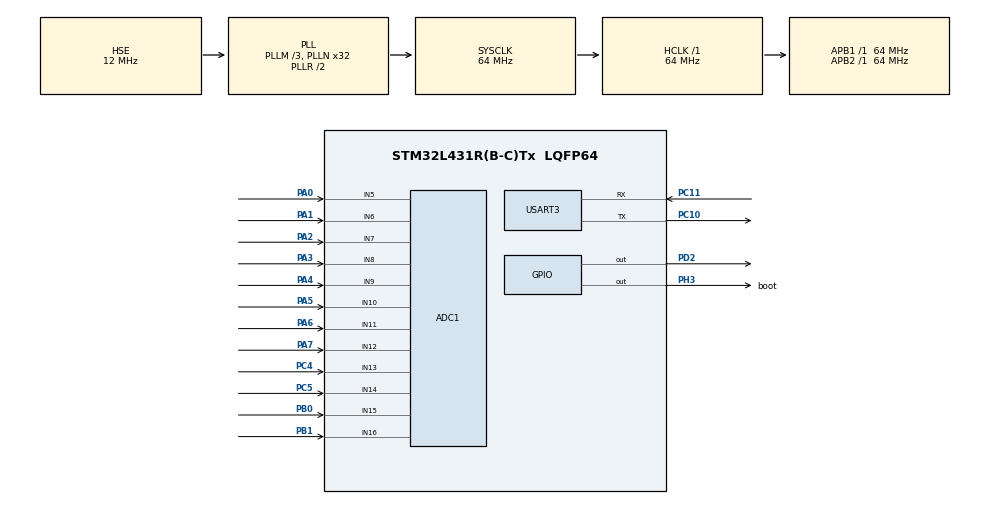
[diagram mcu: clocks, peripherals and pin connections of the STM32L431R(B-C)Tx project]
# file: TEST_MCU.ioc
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ADC1.Channel-0\#ChannelRegularConversion=ADC_CHANNEL_5
ADC1.Channel-1\#ChannelRegularConversion=ADC_CHANNEL_6
ADC1.Channel-10\#ChannelRegularConversion=ADC_CHANNEL_15
ADC1.Channel-11\#ChannelRegularConversion=ADC_CHANNEL_16
ADC1.Channel-2\#ChannelRegularConversion=ADC_CHANNEL_7
ADC1.Channel-3\#ChannelRegularConversion=ADC_CHANNEL_8
ADC1.Channel-4\#ChannelRegularConversion=ADC_CHANNEL_9
ADC1.Channel-5\#ChannelRegularConversion=ADC_CHANNEL_10
ADC1.Channel-6\#ChannelRegularConversion=ADC_CHANNEL_11
ADC1.Channel-7\#ChannelRegularConversion=ADC_CHANNEL_12
ADC1.Channel-8\#ChannelRegularConversion=ADC_CHANNEL_13
ADC1.Channel-9\#ChannelRegularConversion=ADC_CHANNEL_14
ADC1.ContinuousConvMode=ENABLE
ADC1.DMAContinuousRequests=ENABLE
ADC1.EOCSelection=ADC_EOC_SEQ_CONV
ADC1.NbrOfConversion=12
ADC1.NbrOfConversionFlag=1
ADC1.OffsetNumber-0\#ChannelRegularConversion=ADC_OFFSET_NONE
ADC1.OffsetNumber-1\#ChannelRegularConversion=ADC_OFFSET_NONE
ADC1.OffsetNumber-10\#ChannelRegularConversion=ADC_OFFSET_NONE
ADC1.OffsetNumber-11\#ChannelRegularConversion=ADC_OFFSET_NONE
ADC1.OffsetNumber-2\#ChannelRegularConversion=ADC_OFFSET_NONE
ADC1.OffsetNumber-3\#ChannelRegularConversion=ADC_OFFSET_NONE
ADC1.OffsetNumber-4\#ChannelRegularConversion=ADC_OFFSET_NONE
ADC1.OffsetNumber-5\#ChannelRegularConversion=ADC_OFFSET_NONE
ADC1.OffsetNumber-6\#ChannelRegularConversion=ADC_OFFSET_NONE
ADC1.OffsetNumber-7\#ChannelRegularConversion=ADC_OFFSET_NONE
ADC1.OffsetNumber-8\#ChannelRegularConversion=ADC_OFFSET_NONE
ADC1.OffsetNumber-9\#ChannelRegularConversion=ADC_OFFSET_NONE
ADC1.Overrun=ADC_OVR_DATA_OVERWRITTEN
ADC1.Rank-0\#ChannelRegularConversion=1
ADC1.Rank-1\#ChannelRegularConversion=2
ADC1.Rank-10\#ChannelRegularConversion=11
ADC1.Rank-11\#ChannelRegularConversion=12
ADC1.Rank-2\#ChannelRegularConversion=3
ADC1.Rank-3\#ChannelRegularConversion=4
ADC1.Rank-4\#ChannelRegularConversion=5
ADC1.Rank-5\#ChannelRegularConversion=6
ADC1.Rank-6\#ChannelRegularConversion=7
ADC1.Rank-7\#ChannelRegularConversion=8
ADC1.Rank-8\#ChannelRegularConversion=9
ADC1.Rank-9\#ChannelRegularConversion=10
ADC1.SamplingTime-0\#ChannelRegularConversion=ADC_SAMPLETIME_640CYCLES_5
ADC1.SamplingTime-1\#ChannelRegularConversion=ADC_SAMPLETIME_640CYCLES_5
ADC1.SamplingTime-10\#ChannelRegularConversion=ADC_SAMPLETIME_640CYCLES_5
ADC1.SamplingTime-11\#ChannelRegularConversion=ADC_SAMPLETIME_640CYCLES_5
ADC1.SamplingTime-2\#ChannelRegularConversion=ADC_SAMPLETIME_640CYCLES_5
ADC1.SamplingTime-3\#ChannelRegularConversion=ADC_SAMPLETIME_640CYCLES_5
ADC1.SamplingTime-4\#ChannelRegularConversion=ADC_SAMPLETIME_640CYCLES_5
ADC1.SamplingTime-5\#ChannelRegularConversion=ADC_SAMPLETIME_640CYCLES_5
ADC1.SamplingTime-6\#ChannelRegularConversion=ADC_SAMPLETIME_640CYCLES_5
ADC1.SamplingTime-7\#ChannelRegularConversion=ADC_SAMPLETIME_640CYCLES_5
ADC1.SamplingTime-8\#ChannelRegularConversion=ADC_SAMPLETIME_640CYCLES_5
ADC1.SamplingTime-9\#ChannelRegularConversion=ADC_SAMPLETIME_640CYCLES_5
ADC1.master=1
Dma.ADC1.0.Direction=DMA_PERIPH_TO_MEMORY
Dma.ADC1.0.Instance=DMA1_Channel1
Dma.ADC1.0.MemDataAlignment=DMA_MDATAALIGN_HALFWORD
Dma.ADC1.0.MemInc=DMA_MINC_ENABLE
Dma.ADC1.0.Mode=DMA_CIRCULAR
Dma.ADC1.0.PeriphDataAlignment=DMA_PDATAALIGN_HALFWORD
Dma.ADC1.0.PeriphInc=DMA_PINC_DISABLE
Dma.ADC1.0.Priority=DMA_PRIORITY_LOW
Dma.Request0=ADC1
Mcu.Family=STM32L4
Mcu.Name=STM32L431R(B-C)Tx
Mcu.Package=LQFP64
NVIC.DMA1_Channel1_IRQn=true\:0\:0\:false\:false\:true\:false\:true\:true
NVIC.PriorityGroup=NVIC_PRIORITYGROUP_4
PA0.Signal=ADCx_IN5
PA1.Signal=ADCx_IN6
PA13\ (JTMS-SWDIO).Mode=Serial_Wire
PA13\ (JTMS-SWDIO).Signal=SYS_JTMS-SWDIO
PA14\ (JTCK-SWCLK).Mode=Serial_Wire
PA14\ (JTCK-SWCLK).Signal=SYS_JTCK-SWCLK
PA2.Signal=ADCx_IN7
PA3.Signal=ADCx_IN8
PA4.Signal=ADCx_IN9
PA5.Signal=ADCx_IN10
PA6.Signal=ADCx_IN11
PA7.Signal=ADCx_IN12
PB0.Signal=ADCx_IN15
PB1.Signal=ADCx_IN16
PC10.Mode=Asynchronous
PC10.Signal=USART3_TX
PC11.Mode=Asynchronous
PC11.Signal=USART3_RX
PC4.Signal=ADCx_IN13
PC5.Signal=ADCx_IN14
PD2.Signal=GPIO_Output
PH0-OSC_IN\ (PH0).Mode=HSE-External-Oscillator
PH0-OSC_IN\ (PH0).Signal=RCC_OSC_IN
PH1-OSC_OUT\ (PH1).Mode=HSE-External-Oscillator
PH1-OSC_OUT\ (PH1).Signal=RCC_OSC_OUT
PH3-BOOT0.GPIO_Label=boot
PH3-BOOT0.Signal=GPIO_Output
ProjectManager.HeapSize=0x200
ProjectManager.StackSize=0x400
ProjectManager.TargetToolchain=STM32CubeIDE
RCC.ADCFreq_Value=32000000
RCC.AHBFreq_Value=64000000
RCC.APB1Freq_Value=64000000
RCC.APB1TimFreq_Value=64000000
RCC.APB2Freq_Value=64000000
RCC.APB2TimFreq_Value=64000000
RCC.CortexFreq_Value=64000000
RCC.HCLKFreq_Value=64000000
RCC.HSE_VALUE=12000000
RCC.HSI48_VALUE=48000000
RCC.HSI_VALUE=16000000
RCC.LSE_VALUE=32768
RCC.MSI_VALUE=4000000
RCC.PLLM=3
RCC.PLLN=32
RCC.PLLSAI1N=16
RCC.PLLSourceVirtual=RCC_PLLSOURCE_HSE
RCC.SYSCLKFreq_VALUE=64000000
RCC.SYSCLKSource=RCC_SYSCLKSOURCE_PLLCLK
RCC.VCOOutputFreq_Value=128000000
SH.ADCx_IN10.0=ADC1_IN10,IN10-Single-Ended
SH.ADCx_IN11.0=ADC1_IN11,IN11-Single-Ended
SH.ADCx_IN12.0=ADC1_IN12,IN12-Single-Ended
SH.ADCx_IN13.0=ADC1_IN13,IN13-Single-Ended
SH.ADCx_IN14.0=ADC1_IN14,IN14-Single-Ended
SH.ADCx_IN15.0=ADC1_IN15,IN15-Single-Ended
SH.ADCx_IN16.0=ADC1_IN16,IN16-Single-Ended
SH.ADCx_IN5.0=ADC1_IN5,IN5-Single-Ended
SH.ADCx_IN6.0=ADC1_IN6,IN6-Single-Ended
SH.ADCx_IN7.0=ADC1_IN7,IN7-Single-Ended
SH.ADCx_IN8.0=ADC1_IN8,IN8-Single-Ended
SH.ADCx_IN9.0=ADC1_IN9,IN9-Single-Ended
USART3.VirtualMode-Asynchronous=VM_ASYNC
board=custom

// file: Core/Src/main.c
/* USER CODE BEGIN Header */
/**
  ******************************************************************************
  * @file           : main.c
  * @brief          : Main program body
  ******************************************************************************
  * @attention
  *
  * Copyright (c) 2023 STMicroelectronics.
  * All rights reserved.
  *
  * This software is licensed under terms that can be found in the LICENSE file
  * in the root directory of this software component.
  * If no LICENSE file comes with this software, it is provided AS-IS.
  *
  ******************************************************************************
  */
/* USER CODE END Header */
#include "main.h"

ADC_HandleTypeDef hadc1;
DMA_HandleTypeDef hdma_adc1;

UART_HandleTypeDef huart3;

/* USER CODE BEGIN PV */

uint16_t rawData[12];

uint8_t dummy[2] = {1,2};

/* USER CODE END PV */

void SystemClock_Config(void);
static void MX_GPIO_Init(void);
static void MX_DMA_Init(void);
static void MX_ADC1_Init(void);
static void MX_USART3_UART_Init(void);

int main(void)
{

  /* MCU Configuration--------------------------------------------------------*/

  /* Reset of all peripherals, Initializes the Flash interface and the Systick. */
  HAL_Init();

  /* Configure the system clock */
  SystemClock_Config();

  /* Initialize all configured peripherals */
  MX_GPIO_Init();
  MX_DMA_Init();
  MX_ADC1_Init();
  MX_USART3_UART_Init();
  /* USER CODE BEGIN 2 */

  HAL_ADC_Start_DMA(&hadc1, (uint32_t*)rawData, 12);
  /* USER CODE END 2 */

  /* Infinite loop */
  while (1)
  {
	  HAL_UART_Transmit(&huart3, dummy, 2, HAL_MAX_DELAY);
	  HAL_Delay(1000);
  }
}

void SystemClock_Config(void)
{
  RCC_OscInitTypeDef RCC_OscInitStruct = {0};
  RCC_ClkInitTypeDef RCC_ClkInitStruct = {0};

  /** Configure the main internal regulator output voltage
  */
  if (HAL_PWREx_ControlVoltageScaling(PWR_REGULATOR_VOLTAGE_SCALE1) != HAL_OK)
  {
    Error_Handler();
  }

  /** Initializes the RCC Oscillators according to the specified parameters
  * in the RCC_OscInitTypeDef structure.
  */
  RCC_OscInitStruct.OscillatorType = RCC_OSCILLATORTYPE_HSE;
  RCC_OscInitStruct.HSEState = RCC_HSE_ON;
  RCC_OscInitStruct.PLL.PLLState = RCC_PLL_ON;
  RCC_OscInitStruct.PLL.PLLSource = RCC_PLLSOURCE_HSE;
  RCC_OscInitStruct.PLL.PLLM = 3;
  RCC_OscInitStruct.PLL.PLLN = 32;
  RCC_OscInitStruct.PLL.PLLP = RCC_PLLP_DIV7;
  RCC_OscInitStruct.PLL.PLLQ = RCC_PLLQ_DIV2;
  RCC_OscInitStruct.PLL.PLLR = RCC_PLLR_DIV2;
  if (HAL_RCC_OscConfig(&RCC_OscInitStruct) != HAL_OK)
  {
    Error_Handler();
  }

  /** Initializes the CPU, AHB and APB buses clocks
  */
  RCC_ClkInitStruct.ClockType = RCC_CLOCKTYPE_HCLK|RCC_CLOCKTYPE_SYSCLK
                              |RCC_CLOCKTYPE_PCLK1|RCC_CLOCKTYPE_PCLK2;
  RCC_ClkInitStruct.SYSCLKSource = RCC_SYSCLKSOURCE_PLLCLK;
  RCC_ClkInitStruct.AHBCLKDivider = RCC_SYSCLK_DIV1;
  RCC_ClkInitStruct.APB1CLKDivider = RCC_HCLK_DIV1;
  RCC_ClkInitStruct.APB2CLKDivider = RCC_HCLK_DIV1;

  if (HAL_RCC_ClockConfig(&RCC_ClkInitStruct, FLASH_LATENCY_3) != HAL_OK)
  {
    Error_Handler();
  }
}

static void MX_ADC1_Init(void)
{

  ADC_ChannelConfTypeDef sConfig = {0};

  /** Common config
  */
  hadc1.Instance = ADC1;
  hadc1.Init.ClockPrescaler = ADC_CLOCK_ASYNC_DIV1;
  hadc1.Init.Resolution = ADC_RESOLUTION_12B;
  hadc1.Init.DataAlign = ADC_DATAALIGN_RIGHT;
  hadc1.Init.ScanConvMode = ADC_SCAN_ENABLE;
  hadc1.Init.EOCSelection = ADC_EOC_SEQ_CONV;
  hadc1.Init.LowPowerAutoWait = DISABLE;
  hadc1.Init.ContinuousConvMode = ENABLE;
  hadc1.Init.NbrOfConversion = 12;
  hadc1.Init.DiscontinuousConvMode = DISABLE;
  hadc1.Init.ExternalTrigConv = ADC_SOFTWARE_START;
  hadc1.Init.ExternalTrigConvEdge = ADC_EXTERNALTRIGCONVEDGE_NONE;
  hadc1.Init.DMAContinuousRequests = ENABLE;
  hadc1.Init.Overrun = ADC_OVR_DATA_OVERWRITTEN;
  hadc1.Init.OversamplingMode = DISABLE;
  if (HAL_ADC_Init(&hadc1) != HAL_OK)
  {
    Error_Handler();
  }

  /** Configure Regular Channel
  */
  sConfig.Channel = ADC_CHANNEL_5;
  sConfig.Rank = ADC_REGULAR_RANK_1;
  sConfig.SamplingTime = ADC_SAMPLETIME_640CYCLES_5;
  sConfig.SingleDiff = ADC_SINGLE_ENDED;
  sConfig.OffsetNumber = ADC_OFFSET_NONE;
  sConfig.Offset = 0;
  if (HAL_ADC_ConfigChannel(&hadc1, &sConfig) != HAL_OK)
  {
    Error_Handler();
  }

  /** Configure Regular Channel
  */
  sConfig.Channel = ADC_CHANNEL_6;
  sConfig.Rank = ADC_REGULAR_RANK_2;
  if (HAL_ADC_ConfigChannel(&hadc1, &sConfig) != HAL_OK)
  {
    Error_Handler();
  }

  /** Configure Regular Channel
  */
  sConfig.Channel = ADC_CHANNEL_7;
  sConfig.Rank = ADC_REGULAR_RANK_3;
  if (HAL_ADC_ConfigChannel(&hadc1, &sConfig) != HAL_OK)
  {
    Error_Handler();
  }

  /** Configure Regular Channel
  */
  sConfig.Channel = ADC_CHANNEL_8;
  sConfig.Rank = ADC_REGULAR_RANK_4;
  if (HAL_ADC_ConfigChannel(&hadc1, &sConfig) != HAL_OK)
  {
    Error_Handler();
  }

  /** Configure Regular Channel
  */
  sConfig.Channel = ADC_CHANNEL_9;
  sConfig.Rank = ADC_REGULAR_RANK_5;
  if (HAL_ADC_ConfigChannel(&hadc1, &sConfig) != HAL_OK)
  {
    Error_Handler();
  }

  /** Configure Regular Channel
  */
  sConfig.Channel = ADC_CHANNEL_10;
  sConfig.Rank = ADC_REGULAR_RANK_6;
  if (HAL_ADC_ConfigChannel(&hadc1, &sConfig) != HAL_OK)
  {
    Error_Handler();
  }

  /** Configure Regular Channel
  */
  sConfig.Channel = ADC_CHANNEL_11;
  sConfig.Rank = ADC_REGULAR_RANK_7;
  if (HAL_ADC_ConfigChannel(&hadc1, &sConfig) != HAL_OK)
  {
    Error_Handler();
  }

  /** Configure Regular Channel
  */
  sConfig.Channel = ADC_CHANNEL_12;
  sConfig.Rank = ADC_REGULAR_RANK_8;
  if (HAL_ADC_ConfigChannel(&hadc1, &sConfig) != HAL_OK)
  {
    Error_Handler();
  }

  /** Configure Regular Channel
  */
  sConfig.Channel = ADC_CHANNEL_13;
  sConfig.Rank = ADC_REGULAR_RANK_9;
  if (HAL_ADC_ConfigChannel(&hadc1, &sConfig) != HAL_OK)
  {
    Error_Handler();
  }

  /** Configure Regular Channel
  */
  sConfig.Channel = ADC_CHANNEL_14;
  sConfig.Rank = ADC_REGULAR_RANK_10;
  if (HAL_ADC_ConfigChannel(&hadc1, &sConfig) != HAL_OK)
  {
    Error_Handler();
  }

  /** Configure Regular Channel
  */
  sConfig.Channel = ADC_CHANNEL_15;
  sConfig.Rank = ADC_REGULAR_RANK_11;
  if (HAL_ADC_ConfigChannel(&hadc1, &sConfig) != HAL_OK)
  {
    Error_Handler();
  }

  /** Configure Regular Channel
  */
  sConfig.Channel = ADC_CHANNEL_16;
  sConfig.Rank = ADC_REGULAR_RANK_12;
  if (HAL_ADC_ConfigChannel(&hadc1, &sConfig) != HAL_OK)
  {
    Error_Handler();
  }

}

static void MX_USART3_UART_Init(void)
{

  huart3.Instance = USART3;
  huart3.Init.BaudRate = 115200;
  huart3.Init.WordLength = UART_WORDLENGTH_8B;
  huart3.Init.StopBits = UART_STOPBITS_1;
  huart3.Init.Parity = UART_PARITY_NONE;
  huart3.Init.Mode = UART_MODE_TX_RX;
  huart3.Init.HwFlowCtl = UART_HWCONTROL_NONE;
  huart3.Init.OverSampling = UART_OVERSAMPLING_16;
  huart3.Init.OneBitSampling = UART_ONE_BIT_SAMPLE_DISABLE;
  huart3.AdvancedInit.AdvFeatureInit = UART_ADVFEATURE_NO_INIT;
  if (HAL_UART_Init(&huart3) != HAL_OK)
  {
    Error_Handler();
  }

}

static void MX_DMA_Init(void)
{

  /* DMA controller clock enable */
  __HAL_RCC_DMA1_CLK_ENABLE();

  /* DMA interrupt init */
  /* DMA1_Channel1_IRQn interrupt configuration */
  HAL_NVIC_SetPriority(DMA1_Channel1_IRQn, 0, 0);
  HAL_NVIC_EnableIRQ(DMA1_Channel1_IRQn);

}

static void MX_GPIO_Init(void)
{
  GPIO_InitTypeDef GPIO_InitStruct = {0};

  /* GPIO Ports Clock Enable */
  __HAL_RCC_GPIOH_CLK_ENABLE();
  __HAL_RCC_GPIOA_CLK_ENABLE();
  __HAL_RCC_GPIOC_CLK_ENABLE();
  __HAL_RCC_GPIOB_CLK_ENABLE();

  /*Configure GPIO pin Output Level */
  HAL_GPIO_WritePin(boot_GPIO_Port, boot_Pin, GPIO_PIN_RESET);

  /*Configure GPIO pin : boot_Pin */
  GPIO_InitStruct.Pin = boot_Pin;
  GPIO_InitStruct.Mode = GPIO_MODE_OUTPUT_PP;
  GPIO_InitStruct.Pull = GPIO_NOPULL;
  GPIO_InitStruct.Speed = GPIO_SPEED_FREQ_LOW;
  HAL_GPIO_Init(boot_GPIO_Port, &GPIO_InitStruct);

}

/* USER CODE BEGIN 4 */

void HAL_ADC_ConvCpltCallback(ADC_HandleTypeDef *hadc)
{

}

/* USER CODE END 4 */

void Error_Handler(void)
{
  __disable_irq();
  while (1)
  {
  }
}
